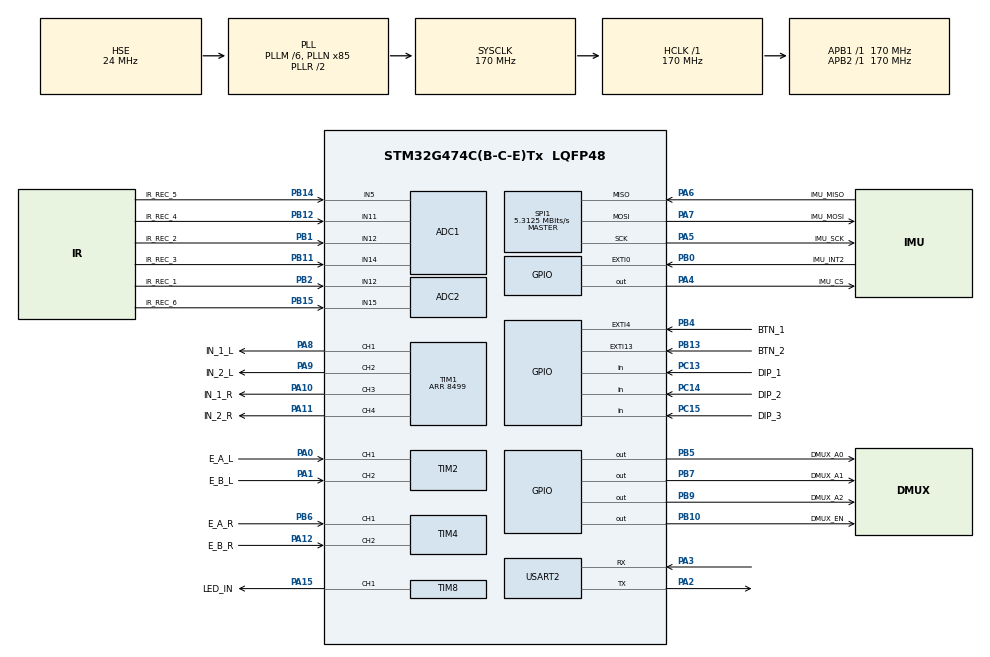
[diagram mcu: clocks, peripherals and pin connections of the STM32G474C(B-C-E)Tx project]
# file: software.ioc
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ADC1.Channel-0\#ChannelRegularConversion=ADC_CHANNEL_12
ADC1.Channel-1\#ChannelRegularConversion=ADC_CHANNEL_14
ADC1.Channel-2\#ChannelRegularConversion=ADC_CHANNEL_11
ADC1.Channel-3\#ChannelRegularConversion=ADC_CHANNEL_5
ADC1.ClockPrescaler=ADC_CLOCK_ASYNC_DIV4
ADC1.ContinuousConvMode=DISABLE
ADC1.DMAContinuousRequests=ENABLE
ADC1.EOCSelection=ADC_EOC_SEQ_CONV
ADC1.NbrOfConversion=4
ADC1.NbrOfConversionFlag=1
ADC1.OffsetNumber-0\#ChannelRegularConversion=ADC_OFFSET_NONE
ADC1.OffsetNumber-1\#ChannelRegularConversion=ADC_OFFSET_NONE
ADC1.OffsetNumber-2\#ChannelRegularConversion=ADC_OFFSET_NONE
ADC1.OffsetNumber-3\#ChannelRegularConversion=ADC_OFFSET_NONE
ADC1.Overrun=ADC_OVR_DATA_OVERWRITTEN
ADC1.Rank-0\#ChannelRegularConversion=1
ADC1.Rank-1\#ChannelRegularConversion=2
ADC1.Rank-2\#ChannelRegularConversion=3
ADC1.Rank-3\#ChannelRegularConversion=4
ADC1.SamplingTime-0\#ChannelRegularConversion=ADC_SAMPLETIME_92CYCLES_5
ADC1.SamplingTime-1\#ChannelRegularConversion=ADC_SAMPLETIME_92CYCLES_5
ADC1.SamplingTime-2\#ChannelRegularConversion=ADC_SAMPLETIME_92CYCLES_5
ADC1.SamplingTime-3\#ChannelRegularConversion=ADC_SAMPLETIME_92CYCLES_5
ADC1.master=1
ADC2.Channel-2\#ChannelRegularConversion=ADC_CHANNEL_12
ADC2.Channel-3\#ChannelRegularConversion=ADC_CHANNEL_15
ADC2.ClockPrescaler=ADC_CLOCK_ASYNC_DIV4
ADC2.ContinuousConvMode=DISABLE
ADC2.DMAContinuousRequests=ENABLE
ADC2.EOCSelection=ADC_EOC_SEQ_CONV
ADC2.NbrOfConversion=2
ADC2.NbrOfConversionFlag=1
ADC2.OffsetNumber-2\#ChannelRegularConversion=ADC_OFFSET_NONE
ADC2.OffsetNumber-3\#ChannelRegularConversion=ADC_OFFSET_NONE
ADC2.Overrun=ADC_OVR_DATA_OVERWRITTEN
ADC2.Rank-2\#ChannelRegularConversion=1
ADC2.Rank-3\#ChannelRegularConversion=2
ADC2.SamplingTime-2\#ChannelRegularConversion=ADC_SAMPLETIME_92CYCLES_5
ADC2.SamplingTime-3\#ChannelRegularConversion=ADC_SAMPLETIME_92CYCLES_5
Dma.ADC1.0.Direction=DMA_PERIPH_TO_MEMORY
Dma.ADC1.0.EventEnable=DISABLE
Dma.ADC1.0.Instance=DMA1_Channel1
Dma.ADC1.0.MemDataAlignment=DMA_MDATAALIGN_HALFWORD
Dma.ADC1.0.MemInc=DMA_MINC_ENABLE
Dma.ADC1.0.Mode=DMA_NORMAL
Dma.ADC1.0.PeriphDataAlignment=DMA_PDATAALIGN_HALFWORD
Dma.ADC1.0.PeriphInc=DMA_PINC_DISABLE
Dma.ADC1.0.Polarity=HAL_DMAMUX_REQ_GEN_RISING
Dma.ADC1.0.Priority=DMA_PRIORITY_HIGH
Dma.ADC1.0.RequestNumber=1
Dma.ADC1.0.SignalID=NONE
Dma.ADC1.0.SyncEnable=DISABLE
Dma.ADC1.0.SyncPolarity=HAL_DMAMUX_SYNC_NO_EVENT
Dma.ADC1.0.SyncRequestNumber=1
Dma.ADC1.0.SyncSignalID=NONE
Dma.ADC2.4.Direction=DMA_PERIPH_TO_MEMORY
Dma.ADC2.4.EventEnable=DISABLE
Dma.ADC2.4.Instance=DMA1_Channel2
Dma.ADC2.4.MemDataAlignment=DMA_MDATAALIGN_HALFWORD
Dma.ADC2.4.MemInc=DMA_MINC_ENABLE
Dma.ADC2.4.Mode=DMA_NORMAL
Dma.ADC2.4.PeriphDataAlignment=DMA_PDATAALIGN_HALFWORD
Dma.ADC2.4.PeriphInc=DMA_PINC_DISABLE
Dma.ADC2.4.Polarity=HAL_DMAMUX_REQ_GEN_RISING
Dma.ADC2.4.Priority=DMA_PRIORITY_HIGH
Dma.ADC2.4.RequestNumber=1
Dma.ADC2.4.SignalID=NONE
Dma.ADC2.4.SyncEnable=DISABLE
Dma.ADC2.4.SyncPolarity=HAL_DMAMUX_SYNC_NO_EVENT
Dma.ADC2.4.SyncRequestNumber=1
Dma.ADC2.4.SyncSignalID=NONE
Dma.Request0=ADC1
Dma.Request1=TIM8_CH1
Dma.Request2=USART2_RX
Dma.Request3=USART2_TX
Dma.Request4=ADC2
Dma.TIM8_CH1.1.Direction=DMA_MEMORY_TO_PERIPH
Dma.TIM8_CH1.1.EventEnable=DISABLE
Dma.TIM8_CH1.1.Instance=DMA1_Channel3
Dma.TIM8_CH1.1.MemDataAlignment=DMA_MDATAALIGN_HALFWORD
Dma.TIM8_CH1.1.MemInc=DMA_MINC_ENABLE
Dma.TIM8_CH1.1.Mode=DMA_NORMAL
Dma.TIM8_CH1.1.PeriphDataAlignment=DMA_PDATAALIGN_HALFWORD
Dma.TIM8_CH1.1.PeriphInc=DMA_PINC_DISABLE
Dma.TIM8_CH1.1.Polarity=HAL_DMAMUX_REQ_GEN_RISING
Dma.TIM8_CH1.1.Priority=DMA_PRIORITY_HIGH
Dma.TIM8_CH1.1.RequestNumber=1
Dma.TIM8_CH1.1.SignalID=NONE
Dma.TIM8_CH1.1.SyncEnable=DISABLE
Dma.TIM8_CH1.1.SyncPolarity=HAL_DMAMUX_SYNC_NO_EVENT
Dma.TIM8_CH1.1.SyncRequestNumber=1
Dma.TIM8_CH1.1.SyncSignalID=NONE
Dma.USART2_RX.2.Direction=DMA_PERIPH_TO_MEMORY
Dma.USART2_RX.2.EventEnable=DISABLE
Dma.USART2_RX.2.Instance=DMA1_Channel4
Dma.USART2_RX.2.MemDataAlignment=DMA_MDATAALIGN_BYTE
Dma.USART2_RX.2.MemInc=DMA_MINC_ENABLE
Dma.USART2_RX.2.Mode=DMA_CIRCULAR
Dma.USART2_RX.2.PeriphDataAlignment=DMA_PDATAALIGN_BYTE
Dma.USART2_RX.2.PeriphInc=DMA_PINC_DISABLE
Dma.USART2_RX.2.Polarity=HAL_DMAMUX_REQ_GEN_RISING
Dma.USART2_RX.2.Priority=DMA_PRIORITY_MEDIUM
Dma.USART2_RX.2.RequestNumber=1
Dma.USART2_RX.2.SignalID=NONE
Dma.USART2_RX.2.SyncEnable=DISABLE
Dma.USART2_RX.2.SyncPolarity=HAL_DMAMUX_SYNC_NO_EVENT
Dma.USART2_RX.2.SyncRequestNumber=1
Dma.USART2_RX.2.SyncSignalID=NONE
Dma.USART2_TX.3.Direction=DMA_MEMORY_TO_PERIPH
Dma.USART2_TX.3.EventEnable=DISABLE
Dma.USART2_TX.3.Instance=DMA1_Channel5
Dma.USART2_TX.3.MemDataAlignment=DMA_MDATAALIGN_BYTE
Dma.USART2_TX.3.MemInc=DMA_MINC_ENABLE
Dma.USART2_TX.3.Mode=DMA_NORMAL
Dma.USART2_TX.3.PeriphDataAlignment=DMA_PDATAALIGN_BYTE
Dma.USART2_TX.3.PeriphInc=DMA_PINC_DISABLE
Dma.USART2_TX.3.Polarity=HAL_DMAMUX_REQ_GEN_RISING
Dma.USART2_TX.3.Priority=DMA_PRIORITY_MEDIUM
Dma.USART2_TX.3.RequestNumber=1
Dma.USART2_TX.3.SignalID=NONE
Dma.USART2_TX.3.SyncEnable=DISABLE
Dma.USART2_TX.3.SyncPolarity=HAL_DMAMUX_SYNC_NO_EVENT
Dma.USART2_TX.3.SyncRequestNumber=1
Dma.USART2_TX.3.SyncSignalID=NONE
Mcu.Family=STM32G4
Mcu.Name=STM32G474C(B-C-E)Tx
Mcu.Package=LQFP48
NVIC.DMA1_Channel1_IRQn=true\:0\:0\:false\:false\:true\:false\:true\:true
NVIC.DMA1_Channel2_IRQn=true\:0\:0\:false\:false\:true\:false\:true\:true
NVIC.DMA1_Channel3_IRQn=true\:0\:0\:false\:false\:true\:false\:true\:true
NVIC.DMA1_Channel4_IRQn=true\:0\:0\:false\:false\:true\:false\:true\:true
NVIC.DMA1_Channel5_IRQn=true\:0\:0\:false\:false\:true\:false\:true\:true
NVIC.EXTI0_IRQn=true\:5\:0\:true\:false\:true\:true\:true\:true
NVIC.EXTI15_10_IRQn=true\:5\:0\:true\:false\:true\:true\:true\:true
NVIC.EXTI4_IRQn=true\:5\:0\:true\:false\:true\:true\:true\:true
NVIC.PriorityGroup=NVIC_PRIORITYGROUP_4
NVIC.TIM1_UP_TIM16_IRQn=true\:0\:0\:false\:false\:true\:true\:true\:true
NVIC.TIM3_IRQn=true\:5\:0\:true\:false\:true\:true\:true\:true
NVIC.TIM6_DAC_IRQn=true\:0\:0\:false\:false\:true\:true\:true\:true
NVIC.TIM7_DAC_IRQn=true\:5\:0\:true\:false\:true\:true\:true\:true
NVIC.USART2_IRQn=true\:0\:0\:false\:false\:true\:false\:true\:true
PA0.GPIO_Label=E_A_L
PA0.Signal=S_TIM2_CH1
PA1.GPIO_Label=E_B_L
PA1.Signal=S_TIM2_CH2
PA10.GPIO_Label=IN_1_R
PA10.Signal=S_TIM1_CH3
PA11.GPIO_Label=IN_2_R
PA11.Signal=S_TIM1_CH4
PA12.GPIO_Label=E_B_R
PA12.Signal=S_TIM4_CH2
PA13.Mode=Trace_Asynchronous_SW
PA13.Signal=SYS_JTMS-SWDIO
PA14.Mode=Trace_Asynchronous_SW
PA14.Signal=SYS_JTCK-SWCLK
PA15.GPIO_Label=LED_IN
PA15.GPIO_Speed=GPIO_SPEED_FREQ_VERY_HIGH
PA15.Signal=S_TIM8_CH1
PA2.Mode=Asynchronous
PA2.Signal=USART2_TX
PA3.Mode=Asynchronous
PA3.Signal=USART2_RX
PA4.GPIO_Label=IMU_CS
PA4.GPIO_PuPd=GPIO_PULLUP
PA4.PinState=GPIO_PIN_SET
PA4.Signal=GPIO_Output
PA5.GPIO_Label=IMU_SCK
PA5.Mode=Full_Duplex_Master
PA5.Signal=SPI1_SCK
PA6.GPIO_Label=IMU_MISO
PA6.Mode=Full_Duplex_Master
PA6.Signal=SPI1_MISO
PA7.GPIO_Label=IMU_MOSI
PA7.Mode=Full_Duplex_Master
PA7.Signal=SPI1_MOSI
PA8.GPIO_Label=IN_1_L
PA8.Signal=S_TIM1_CH1
PA9.GPIO_Label=IN_2_L
PA9.Signal=S_TIM1_CH2
PB0.GPIO_Label=IMU_INT2
PB0.Signal=GPXTI0
PB1.GPIO_Label=IR_REC_2
PB1.Mode=IN12-Single-Ended
PB1.Signal=ADC1_IN12
PB10.GPIO_Label=DMUX_EN
PB10.Signal=GPIO_Output
PB11.GPIO_Label=IR_REC_3
PB11.Mode=IN14-Single-Ended
PB11.Signal=ADC1_IN14
PB12.GPIO_Label=IR_REC_4
PB12.Mode=IN11-Single-Ended
PB12.Signal=ADC1_IN11
PB13.GPIO_Label=BTN_2
PB13.GPIO_ModeDefaultEXTI=GPIO_MODE_IT_FALLING
PB13.Signal=GPXTI13
PB14.GPIO_Label=IR_REC_5
PB14.Mode=IN5-Single-Ended
PB14.Signal=ADC1_IN5
PB15.GPIO_Label=IR_REC_6
PB15.Mode=IN15-Single-Ended
PB15.Signal=ADC2_IN15
PB2.GPIO_Label=IR_REC_1
PB2.Mode=IN12-Single-Ended
PB2.Signal=ADC2_IN12
PB3.Mode=Trace_Asynchronous_SW
PB3.Signal=SYS_JTDO-SWO
PB4.GPIO_Label=BTN_1
PB4.GPIO_ModeDefaultEXTI=GPIO_MODE_IT_FALLING
PB4.Signal=GPXTI4
PB5.GPIO_Label=DMUX_A0
PB5.Signal=GPIO_Output
PB6.GPIO_Label=E_A_R
PB6.Signal=S_TIM4_CH1
PB7.GPIO_Label=DMUX_A1
PB7.Signal=GPIO_Output
PB9.GPIO_Label=DMUX_A2
PB9.Signal=GPIO_Output
PC13.GPIO_Label=DIP_1
PC13.Signal=GPIO_Input
PC14-OSC32_IN.GPIO_Label=DIP_2
PC14-OSC32_IN.Signal=GPIO_Input
PC15-OSC32_OUT.GPIO_Label=DIP_3
PC15-OSC32_OUT.Signal=GPIO_Input
PF0-OSC_IN.Mode=HSE-External-Oscillator
PF0-OSC_IN.Signal=RCC_OSC_IN
PF1-OSC_OUT.Mode=HSE-External-Oscillator
PF1-OSC_OUT.Signal=RCC_OSC_OUT
ProjectManager.HeapSize=0x200
ProjectManager.StackSize=0x400
ProjectManager.TargetToolchain=STM32CubeIDE
RCC.ADC12Freq_Value=170000000
RCC.ADC345Freq_Value=170000000
RCC.AHBFreq_Value=170000000
RCC.APB1Freq_Value=170000000
RCC.APB1TimFreq_Value=170000000
RCC.APB2Freq_Value=170000000
RCC.APB2TimFreq_Value=170000000
RCC.CortexFreq_Value=170000000
RCC.EXTERNAL_CLOCK_VALUE=12288000
RCC.HCLKFreq_Value=170000000
RCC.HSE_VALUE=24000000
RCC.HSI48_VALUE=48000000
RCC.HSI_VALUE=16000000
RCC.LSE_VALUE=32768
RCC.PLLM=RCC_PLLM_DIV6
RCC.PLLN=85
RCC.PLLSourceVirtual=RCC_PLLSOURCE_HSE
RCC.SYSCLKFreq_VALUE=170000000
RCC.SYSCLKSource=RCC_SYSCLKSOURCE_PLLCLK
RCC.USBFreq_Value=170000000
RCC.VCOOutputFreq_Value=340000000
SH.S_TIM1_CH1.0=TIM1_CH1,PWM Generation1 CH1
SH.S_TIM1_CH2.0=TIM1_CH2,PWM Generation2 CH2
SH.S_TIM1_CH3.0=TIM1_CH3,PWM Generation3 CH3
SH.S_TIM1_CH4.0=TIM1_CH4,PWM Generation4 CH4
SH.S_TIM2_CH1.0=TIM2_CH1,Encoder_Interface
SH.S_TIM2_CH2.0=TIM2_CH2,Encoder_Interface
SH.S_TIM4_CH1.0=TIM4_CH1,Encoder_Interface
SH.S_TIM4_CH2.0=TIM4_CH2,Encoder_Interface
SH.S_TIM8_CH1.0=TIM8_CH1,PWM Generation1 CH1
SPI1.BaudRatePrescaler=SPI_BAUDRATEPRESCALER_32
SPI1.CLKPhase=SPI_PHASE_2EDGE
SPI1.CLKPolarity=SPI_POLARITY_HIGH
SPI1.CalculateBaudRate=5.3125 MBits/s
SPI1.DataSize=SPI_DATASIZE_8BIT
SPI1.Direction=SPI_DIRECTION_2LINES
SPI1.Mode=SPI_MODE_MASTER
SPI1.VirtualType=VM_MASTER
TIM1.Channel-PWM\ Generation1\ CH1=TIM_CHANNEL_1
TIM1.Channel-PWM\ Generation2\ CH2=TIM_CHANNEL_2
TIM1.Channel-PWM\ Generation3\ CH3=TIM_CHANNEL_3
TIM1.Channel-PWM\ Generation4\ CH4=TIM_CHANNEL_4
TIM1.PeriodNoDither=8499
TIM16.Prescaler=169
TIM2.EncoderMode=TIM_ENCODERMODE_TI12
TIM3.PeriodNoDither=9
TIM3.Prescaler=16999
TIM4.EncoderMode=TIM_ENCODERMODE_TI12
TIM6.AutoReloadPreload=TIM_AUTORELOAD_PRELOAD_ENABLE
TIM6.PeriodNoDither=99
TIM6.Prescaler=16999
TIM7.AutoReloadPreload=TIM_AUTORELOAD_PRELOAD_ENABLE
TIM7.PeriodNoDither=199
TIM7.Prescaler=16999
TIM8.AutoReloadPreload=TIM_AUTORELOAD_PRELOAD_ENABLE
TIM8.Channel-PWM\ Generation1\ CH1=TIM_CHANNEL_1
TIM8.PeriodNoDither=211
USART2.VirtualMode-Asynchronous=VM_ASYNC
VP_SYS_VS_DBSignals.Mode=DisableDeadBatterySignals
VP_TIM16_VS_ClockSourceINT.Mode=Enable_Timer
VP_TIM1_VS_ClockSourceINT.Mode=Internal
VP_TIM3_VS_ClockSourceINT.Mode=Internal
VP_TIM6_VS_ClockSourceINT.Mode=Enable_Timer
VP_TIM7_VS_ClockSourceINT.Mode=Enable_Timer
VP_TIM8_VS_ClockSourceINT.Mode=Internal
board=custom

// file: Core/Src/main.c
/* USER CODE BEGIN Header */
/**
  ******************************************************************************
  * @file           : main.c
  * @brief          : Main program body
  ******************************************************************************
  * @attention
  *
  * Copyright (c) 2026 STMicroelectronics.
  * All rights reserved.
  *
  * This software is licensed under terms that can be found in the LICENSE file
  * in the root directory of this software component.
  * If no LICENSE file comes with this software, it is provided AS-IS.
  *
  ******************************************************************************
  */
/* USER CODE END Header */
#include "main.h"

/* USER CODE BEGIN Includes */

#include "app.h"

/* USER CODE END Includes */

ADC_HandleTypeDef hadc1;
ADC_HandleTypeDef hadc2;
DMA_HandleTypeDef hdma_adc1;
DMA_HandleTypeDef hdma_adc2;

SPI_HandleTypeDef hspi1;

TIM_HandleTypeDef htim1;
TIM_HandleTypeDef htim2;
TIM_HandleTypeDef htim3;
TIM_HandleTypeDef htim4;
TIM_HandleTypeDef htim6;
TIM_HandleTypeDef htim7;
TIM_HandleTypeDef htim8;
TIM_HandleTypeDef htim16;
DMA_HandleTypeDef hdma_tim8_ch1;

UART_HandleTypeDef huart2;
DMA_HandleTypeDef hdma_usart2_rx;
DMA_HandleTypeDef hdma_usart2_tx;

void SystemClock_Config(void);
static void MX_GPIO_Init(void);
static void MX_DMA_Init(void);
static void MX_ADC1_Init(void);
static void MX_ADC2_Init(void);
static void MX_SPI1_Init(void);
static void MX_TIM1_Init(void);
static void MX_TIM2_Init(void);
static void MX_TIM4_Init(void);
static void MX_TIM8_Init(void);
static void MX_USART2_UART_Init(void);
static void MX_TIM7_Init(void);
static void MX_TIM6_Init(void);
static void MX_TIM3_Init(void);
static void MX_TIM16_Init(void);

int main(void)
{

  /* MCU Configuration--------------------------------------------------------*/

  /* Reset of all peripherals, Initializes the Flash interface and the Systick. */
  HAL_Init();

  /* Configure the system clock */
  SystemClock_Config();

  /* Initialize all configured peripherals */
  MX_GPIO_Init();
  MX_DMA_Init();
  MX_ADC1_Init();
  MX_ADC2_Init();
  MX_SPI1_Init();
  MX_TIM1_Init();
  MX_TIM2_Init();
  MX_TIM3_Init();
  MX_TIM4_Init();
  MX_TIM6_Init();
  MX_TIM7_Init();
  MX_TIM8_Init();
  MX_TIM16_Init();
  MX_USART2_UART_Init();
  /* USER CODE BEGIN 2 */

  App_Init();

  /* USER CODE END 2 */

  /* Infinite loop */
  /* USER CODE BEGIN WHILE */

  while (1)
  {
	  App_Loop();
  }

    /* USER CODE END WHILE */

    /* USER CODE BEGIN 3 */
//  }
  /* USER CODE END 3 */
}

void SystemClock_Config(void)
{
  RCC_OscInitTypeDef RCC_OscInitStruct = {0};
  RCC_ClkInitTypeDef RCC_ClkInitStruct = {0};

  /** Configure the main internal regulator output voltage
  */
  HAL_PWREx_ControlVoltageScaling(PWR_REGULATOR_VOLTAGE_SCALE1_BOOST);

  /** Initializes the RCC Oscillators according to the specified parameters
  * in the RCC_OscInitTypeDef structure.
  */
  RCC_OscInitStruct.OscillatorType = RCC_OSCILLATORTYPE_HSE;
  RCC_OscInitStruct.HSEState = RCC_HSE_ON;
  RCC_OscInitStruct.PLL.PLLState = RCC_PLL_ON;
  RCC_OscInitStruct.PLL.PLLSource = RCC_PLLSOURCE_HSE;
  RCC_OscInitStruct.PLL.PLLM = RCC_PLLM_DIV6;
  RCC_OscInitStruct.PLL.PLLN = 85;
  RCC_OscInitStruct.PLL.PLLP = RCC_PLLP_DIV2;
  RCC_OscInitStruct.PLL.PLLQ = RCC_PLLQ_DIV2;
  RCC_OscInitStruct.PLL.PLLR = RCC_PLLR_DIV2;
  if (HAL_RCC_OscConfig(&RCC_OscInitStruct) != HAL_OK)
  {
    Error_Handler();
  }

  /** Initializes the CPU, AHB and APB buses clocks
  */
  RCC_ClkInitStruct.ClockType = RCC_CLOCKTYPE_HCLK|RCC_CLOCKTYPE_SYSCLK
                              |RCC_CLOCKTYPE_PCLK1|RCC_CLOCKTYPE_PCLK2;
  RCC_ClkInitStruct.SYSCLKSource = RCC_SYSCLKSOURCE_PLLCLK;
  RCC_ClkInitStruct.AHBCLKDivider = RCC_SYSCLK_DIV1;
  RCC_ClkInitStruct.APB1CLKDivider = RCC_HCLK_DIV1;
  RCC_ClkInitStruct.APB2CLKDivider = RCC_HCLK_DIV1;

  if (HAL_RCC_ClockConfig(&RCC_ClkInitStruct, FLASH_LATENCY_4) != HAL_OK)
  {
    Error_Handler();
  }
}

static void MX_ADC1_Init(void)
{

  ADC_MultiModeTypeDef multimode = {0};
  ADC_ChannelConfTypeDef sConfig = {0};

  /** Common config
  */
  hadc1.Instance = ADC1;
  hadc1.Init.ClockPrescaler = ADC_CLOCK_ASYNC_DIV4;
  hadc1.Init.Resolution = ADC_RESOLUTION_12B;
  hadc1.Init.DataAlign = ADC_DATAALIGN_RIGHT;
  hadc1.Init.GainCompensation = 0;
  hadc1.Init.ScanConvMode = ADC_SCAN_ENABLE;
  hadc1.Init.EOCSelection = ADC_EOC_SEQ_CONV;
  hadc1.Init.LowPowerAutoWait = DISABLE;
  hadc1.Init.ContinuousConvMode = DISABLE;
  hadc1.Init.NbrOfConversion = 4;
  hadc1.Init.DiscontinuousConvMode = DISABLE;
  hadc1.Init.ExternalTrigConv = ADC_SOFTWARE_START;
  hadc1.Init.ExternalTrigConvEdge = ADC_EXTERNALTRIGCONVEDGE_NONE;
  hadc1.Init.DMAContinuousRequests = ENABLE;
  hadc1.Init.Overrun = ADC_OVR_DATA_OVERWRITTEN;
  hadc1.Init.OversamplingMode = DISABLE;
  if (HAL_ADC_Init(&hadc1) != HAL_OK)
  {
    Error_Handler();
  }

  /** Configure the ADC multi-mode
  */
  multimode.Mode = ADC_MODE_INDEPENDENT;
  if (HAL_ADCEx_MultiModeConfigChannel(&hadc1, &multimode) != HAL_OK)
  {
    Error_Handler();
  }

  /** Configure Regular Channel
  */
  sConfig.Channel = ADC_CHANNEL_12;
  sConfig.Rank = ADC_REGULAR_RANK_1;
  sConfig.SamplingTime = ADC_SAMPLETIME_92CYCLES_5;
  sConfig.SingleDiff = ADC_SINGLE_ENDED;
  sConfig.OffsetNumber = ADC_OFFSET_NONE;
  sConfig.Offset = 0;
  if (HAL_ADC_ConfigChannel(&hadc1, &sConfig) != HAL_OK)
  {
    Error_Handler();
  }

  /** Configure Regular Channel
  */
  sConfig.Channel = ADC_CHANNEL_14;
  sConfig.Rank = ADC_REGULAR_RANK_2;
  if (HAL_ADC_ConfigChannel(&hadc1, &sConfig) != HAL_OK)
  {
    Error_Handler();
  }

  /** Configure Regular Channel
  */
  sConfig.Channel = ADC_CHANNEL_11;
  sConfig.Rank = ADC_REGULAR_RANK_3;
  if (HAL_ADC_ConfigChannel(&hadc1, &sConfig) != HAL_OK)
  {
    Error_Handler();
  }

  /** Configure Regular Channel
  */
  sConfig.Channel = ADC_CHANNEL_5;
  sConfig.Rank = ADC_REGULAR_RANK_4;
  if (HAL_ADC_ConfigChannel(&hadc1, &sConfig) != HAL_OK)
  {
    Error_Handler();
  }

}

static void MX_ADC2_Init(void)
{

  ADC_ChannelConfTypeDef sConfig = {0};

  /** Common config
  */
  hadc2.Instance = ADC2;
  hadc2.Init.ClockPrescaler = ADC_CLOCK_ASYNC_DIV4;
  hadc2.Init.Resolution = ADC_RESOLUTION_12B;
  hadc2.Init.DataAlign = ADC_DATAALIGN_RIGHT;
  hadc2.Init.GainCompensation = 0;
  hadc2.Init.ScanConvMode = ADC_SCAN_ENABLE;
  hadc2.Init.EOCSelection = ADC_EOC_SEQ_CONV;
  hadc2.Init.LowPowerAutoWait = DISABLE;
  hadc2.Init.ContinuousConvMode = DISABLE;
  hadc2.Init.NbrOfConversion = 2;
  hadc2.Init.DiscontinuousConvMode = DISABLE;
  hadc2.Init.ExternalTrigConv = ADC_SOFTWARE_START;
  hadc2.Init.ExternalTrigConvEdge = ADC_EXTERNALTRIGCONVEDGE_NONE;
  hadc2.Init.DMAContinuousRequests = ENABLE;
  hadc2.Init.Overrun = ADC_OVR_DATA_OVERWRITTEN;
  hadc2.Init.OversamplingMode = DISABLE;
  if (HAL_ADC_Init(&hadc2) != HAL_OK)
  {
    Error_Handler();
  }

  /** Configure Regular Channel
  */
  sConfig.Channel = ADC_CHANNEL_12;
  sConfig.Rank = ADC_REGULAR_RANK_1;
  sConfig.SamplingTime = ADC_SAMPLETIME_92CYCLES_5;
  sConfig.SingleDiff = ADC_SINGLE_ENDED;
  sConfig.OffsetNumber = ADC_OFFSET_NONE;
  sConfig.Offset = 0;
  if (HAL_ADC_ConfigChannel(&hadc2, &sConfig) != HAL_OK)
  {
    Error_Handler();
  }

  /** Configure Regular Channel
  */
  sConfig.Channel = ADC_CHANNEL_15;
  sConfig.Rank = ADC_REGULAR_RANK_2;
  if (HAL_ADC_ConfigChannel(&hadc2, &sConfig) != HAL_OK)
  {
    Error_Handler();
  }

}

static void MX_SPI1_Init(void)
{

  /* SPI1 parameter configuration*/
  hspi1.Instance = SPI1;
  hspi1.Init.Mode = SPI_MODE_MASTER;
  hspi1.Init.Direction = SPI_DIRECTION_2LINES;
  hspi1.Init.DataSize = SPI_DATASIZE_8BIT;
  hspi1.Init.CLKPolarity = SPI_POLARITY_HIGH;
  hspi1.Init.CLKPhase = SPI_PHASE_2EDGE;
  hspi1.Init.NSS = SPI_NSS_SOFT;
  hspi1.Init.BaudRatePrescaler = SPI_BAUDRATEPRESCALER_32;
  hspi1.Init.FirstBit = SPI_FIRSTBIT_MSB;
  hspi1.Init.TIMode = SPI_TIMODE_DISABLE;
  hspi1.Init.CRCCalculation = SPI_CRCCALCULATION_DISABLE;
  hspi1.Init.CRCPolynomial = 7;
  hspi1.Init.CRCLength = SPI_CRC_LENGTH_DATASIZE;
  hspi1.Init.NSSPMode = SPI_NSS_PULSE_DISABLE;
  if (HAL_SPI_Init(&hspi1) != HAL_OK)
  {
    Error_Handler();
  }

}

static void MX_TIM1_Init(void)
{

  TIM_ClockConfigTypeDef sClockSourceConfig = {0};
  TIM_MasterConfigTypeDef sMasterConfig = {0};
  TIM_OC_InitTypeDef sConfigOC = {0};
  TIM_BreakDeadTimeConfigTypeDef sBreakDeadTimeConfig = {0};

  htim1.Instance = TIM1;
  htim1.Init.Prescaler = 0;
  htim1.Init.CounterMode = TIM_COUNTERMODE_UP;
  htim1.Init.Period = 8499;
  htim1.Init.ClockDivision = TIM_CLOCKDIVISION_DIV1;
  htim1.Init.RepetitionCounter = 0;
  htim1.Init.AutoReloadPreload = TIM_AUTORELOAD_PRELOAD_DISABLE;
  if (HAL_TIM_Base_Init(&htim1) != HAL_OK)
  {
    Error_Handler();
  }
  sClockSourceConfig.ClockSource = TIM_CLOCKSOURCE_INTERNAL;
  if (HAL_TIM_ConfigClockSource(&htim1, &sClockSourceConfig) != HAL_OK)
  {
    Error_Handler();
  }
  if (HAL_TIM_PWM_Init(&htim1) != HAL_OK)
  {
    Error_Handler();
  }
  sMasterConfig.MasterOutputTrigger = TIM_TRGO_RESET;
  sMasterConfig.MasterOutputTrigger2 = TIM_TRGO2_RESET;
  sMasterConfig.MasterSlaveMode = TIM_MASTERSLAVEMODE_DISABLE;
  if (HAL_TIMEx_MasterConfigSynchronization(&htim1, &sMasterConfig) != HAL_OK)
  {
    Error_Handler();
  }
  sConfigOC.OCMode = TIM_OCMODE_PWM1;
  sConfigOC.Pulse = 0;
  sConfigOC.OCPolarity = TIM_OCPOLARITY_HIGH;
  sConfigOC.OCNPolarity = TIM_OCNPOLARITY_HIGH;
  sConfigOC.OCFastMode = TIM_OCFAST_DISABLE;
  sConfigOC.OCIdleState = TIM_OCIDLESTATE_RESET;
  sConfigOC.OCNIdleState = TIM_OCNIDLESTATE_RESET;
  if (HAL_TIM_PWM_ConfigChannel(&htim1, &sConfigOC, TIM_CHANNEL_1) != HAL_OK)
  {
    Error_Handler();
  }
  if (HAL_TIM_PWM_ConfigChannel(&htim1, &sConfigOC, TIM_CHANNEL_2) != HAL_OK)
  {
    Error_Handler();
  }
  if (HAL_TIM_PWM_ConfigChannel(&htim1, &sConfigOC, TIM_CHANNEL_3) != HAL_OK)
  {
    Error_Handler();
  }
  if (HAL_TIM_PWM_ConfigChannel(&htim1, &sConfigOC, TIM_CHANNEL_4) != HAL_OK)
  {
    Error_Handler();
  }
  sBreakDeadTimeConfig.OffStateRunMode = TIM_OSSR_DISABLE;
  sBreakDeadTimeConfig.OffStateIDLEMode = TIM_OSSI_DISABLE;
  sBreakDeadTimeConfig.LockLevel = TIM_LOCKLEVEL_OFF;
  sBreakDeadTimeConfig.DeadTime = 0;
  sBreakDeadTimeConfig.BreakState = TIM_BREAK_DISABLE;
  sBreakDeadTimeConfig.BreakPolarity = TIM_BREAKPOLARITY_HIGH;
  sBreakDeadTimeConfig.BreakFilter = 0;
  sBreakDeadTimeConfig.BreakAFMode = TIM_BREAK_AFMODE_INPUT;
  sBreakDeadTimeConfig.Break2State = TIM_BREAK2_DISABLE;
  sBreakDeadTimeConfig.Break2Polarity = TIM_BREAK2POLARITY_HIGH;
  sBreakDeadTimeConfig.Break2Filter = 0;
  sBreakDeadTimeConfig.Break2AFMode = TIM_BREAK_AFMODE_INPUT;
  sBreakDeadTimeConfig.AutomaticOutput = TIM_AUTOMATICOUTPUT_DISABLE;
  if (HAL_TIMEx_ConfigBreakDeadTime(&htim1, &sBreakDeadTimeConfig) != HAL_OK)
  {
    Error_Handler();
  }
  HAL_TIM_MspPostInit(&htim1);

}

static void MX_TIM2_Init(void)
{

  TIM_Encoder_InitTypeDef sConfig = {0};
  TIM_MasterConfigTypeDef sMasterConfig = {0};

  htim2.Instance = TIM2;
  htim2.Init.Prescaler = 0;
  htim2.Init.CounterMode = TIM_COUNTERMODE_UP;
  htim2.Init.Period = 4294967295;
  htim2.Init.ClockDivision = TIM_CLOCKDIVISION_DIV1;
  htim2.Init.AutoReloadPreload = TIM_AUTORELOAD_PRELOAD_DISABLE;
  sConfig.EncoderMode = TIM_ENCODERMODE_TI12;
  sConfig.IC1Polarity = TIM_ICPOLARITY_RISING;
  sConfig.IC1Selection = TIM_ICSELECTION_DIRECTTI;
  sConfig.IC1Prescaler = TIM_ICPSC_DIV1;
  sConfig.IC1Filter = 0;
  sConfig.IC2Polarity = TIM_ICPOLARITY_RISING;
  sConfig.IC2Selection = TIM_ICSELECTION_DIRECTTI;
  sConfig.IC2Prescaler = TIM_ICPSC_DIV1;
  sConfig.IC2Filter = 0;
  if (HAL_TIM_Encoder_Init(&htim2, &sConfig) != HAL_OK)
  {
    Error_Handler();
  }
  sMasterConfig.MasterOutputTrigger = TIM_TRGO_RESET;
  sMasterConfig.MasterSlaveMode = TIM_MASTERSLAVEMODE_DISABLE;
  if (HAL_TIMEx_MasterConfigSynchronization(&htim2, &sMasterConfig) != HAL_OK)
  {
    Error_Handler();
  }

}

static void MX_TIM3_Init(void)
{

  TIM_ClockConfigTypeDef sClockSourceConfig = {0};
  TIM_MasterConfigTypeDef sMasterConfig = {0};

  htim3.Instance = TIM3;
  htim3.Init.Prescaler = 16999;
  htim3.Init.CounterMode = TIM_COUNTERMODE_UP;
  htim3.Init.Period = 9;
  htim3.Init.ClockDivision = TIM_CLOCKDIVISION_DIV1;
  htim3.Init.AutoReloadPreload = TIM_AUTORELOAD_PRELOAD_DISABLE;
  if (HAL_TIM_Base_Init(&htim3) != HAL_OK)
  {
    Error_Handler();
  }
  sClockSourceConfig.ClockSource = TIM_CLOCKSOURCE_INTERNAL;
  if (HAL_TIM_ConfigClockSource(&htim3, &sClockSourceConfig) != HAL_OK)
  {
    Error_Handler();
  }
  sMasterConfig.MasterOutputTrigger = TIM_TRGO_RESET;
  sMasterConfig.MasterSlaveMode = TIM_MASTERSLAVEMODE_DISABLE;
  if (HAL_TIMEx_MasterConfigSynchronization(&htim3, &sMasterConfig) != HAL_OK)
  {
    Error_Handler();
  }

}

static void MX_TIM4_Init(void)
{

  TIM_Encoder_InitTypeDef sConfig = {0};
  TIM_MasterConfigTypeDef sMasterConfig = {0};

  htim4.Instance = TIM4;
  htim4.Init.Prescaler = 0;
  htim4.Init.CounterMode = TIM_COUNTERMODE_UP;
  htim4.Init.Period = 65535;
  htim4.Init.ClockDivision = TIM_CLOCKDIVISION_DIV1;
  htim4.Init.AutoReloadPreload = TIM_AUTORELOAD_PRELOAD_DISABLE;
  sConfig.EncoderMode = TIM_ENCODERMODE_TI12;
  sConfig.IC1Polarity = TIM_ICPOLARITY_RISING;
  sConfig.IC1Selection = TIM_ICSELECTION_DIRECTTI;
  sConfig.IC1Prescaler = TIM_ICPSC_DIV1;
  sConfig.IC1Filter = 0;
  sConfig.IC2Polarity = TIM_ICPOLARITY_RISING;
  sConfig.IC2Selection = TIM_ICSELECTION_DIRECTTI;
  sConfig.IC2Prescaler = TIM_ICPSC_DIV1;
  sConfig.IC2Filter = 0;
  if (HAL_TIM_Encoder_Init(&htim4, &sConfig) != HAL_OK)
  {
    Error_Handler();
  }
  sMasterConfig.MasterOutputTrigger = TIM_TRGO_RESET;
  sMasterConfig.MasterSlaveMode = TIM_MASTERSLAVEMODE_DISABLE;
  if (HAL_TIMEx_MasterConfigSynchronization(&htim4, &sMasterConfig) != HAL_OK)
  {
    Error_Handler();
  }

}

static void MX_TIM6_Init(void)
{

  TIM_MasterConfigTypeDef sMasterConfig = {0};

  htim6.Instance = TIM6;
  htim6.Init.Prescaler = 16999;
  htim6.Init.CounterMode = TIM_COUNTERMODE_UP;
  htim6.Init.Period = 99;
  htim6.Init.AutoReloadPreload = TIM_AUTORELOAD_PRELOAD_ENABLE;
  if (HAL_TIM_Base_Init(&htim6) != HAL_OK)
  {
    Error_Handler();
  }
  sMasterConfig.MasterOutputTrigger = TIM_TRGO_RESET;
  sMasterConfig.MasterSlaveMode = TIM_MASTERSLAVEMODE_DISABLE;
  if (HAL_TIMEx_MasterConfigSynchronization(&htim6, &sMasterConfig) != HAL_OK)
  {
    Error_Handler();
  }

}

static void MX_TIM7_Init(void)
{

  /* USER CODE BEGIN TIM7_Init 0 */
  __HAL_RCC_TIM7_CLK_ENABLE();
  /* USER CODE END TIM7_Init 0 */

  TIM_MasterConfigTypeDef sMasterConfig = {0};

  htim7.Instance = TIM7;
  htim7.Init.Prescaler = 16999;
  htim7.Init.CounterMode = TIM_COUNTERMODE_UP;
  htim7.Init.Period = 199;
  htim7.Init.AutoReloadPreload = TIM_AUTORELOAD_PRELOAD_ENABLE;
  if (HAL_TIM_Base_Init(&htim7) != HAL_OK)
  {
    Error_Handler();
  }
  sMasterConfig.MasterOutputTrigger = TIM_TRGO_RESET;
  sMasterConfig.MasterSlaveMode = TIM_MASTERSLAVEMODE_DISABLE;
  if (HAL_TIMEx_MasterConfigSynchronization(&htim7, &sMasterConfig) != HAL_OK)
  {
    Error_Handler();
  }

}

static void MX_TIM8_Init(void)
{

  TIM_ClockConfigTypeDef sClockSourceConfig = {0};
  TIM_MasterConfigTypeDef sMasterConfig = {0};
  TIM_OC_InitTypeDef sConfigOC = {0};
  TIM_BreakDeadTimeConfigTypeDef sBreakDeadTimeConfig = {0};

  htim8.Instance = TIM8;
  htim8.Init.Prescaler = 0;
  htim8.Init.CounterMode = TIM_COUNTERMODE_UP;
  htim8.Init.Period = 211;
  htim8.Init.ClockDivision = TIM_CLOCKDIVISION_DIV1;
  htim8.Init.RepetitionCounter = 0;
  htim8.Init.AutoReloadPreload = TIM_AUTORELOAD_PRELOAD_ENABLE;
  if (HAL_TIM_Base_Init(&htim8) != HAL_OK)
  {
    Error_Handler();
  }
  sClockSourceConfig.ClockSource = TIM_CLOCKSOURCE_INTERNAL;
  if (HAL_TIM_ConfigClockSource(&htim8, &sClockSourceConfig) != HAL_OK)
  {
    Error_Handler();
  }
  if (HAL_TIM_PWM_Init(&htim8) != HAL_OK)
  {
    Error_Handler();
  }
  sMasterConfig.MasterOutputTrigger = TIM_TRGO_RESET;
  sMasterConfig.MasterOutputTrigger2 = TIM_TRGO2_RESET;
  sMasterConfig.MasterSlaveMode = TIM_MASTERSLAVEMODE_DISABLE;
  if (HAL_TIMEx_MasterConfigSynchronization(&htim8, &sMasterConfig) != HAL_OK)
  {
    Error_Handler();
  }
  sConfigOC.OCMode = TIM_OCMODE_PWM1;
  sConfigOC.Pulse = 0;
  sConfigOC.OCPolarity = TIM_OCPOLARITY_HIGH;
  sConfigOC.OCNPolarity = TIM_OCNPOLARITY_HIGH;
  sConfigOC.OCFastMode = TIM_OCFAST_DISABLE;
  sConfigOC.OCIdleState = TIM_OCIDLESTATE_RESET;
  sConfigOC.OCNIdleState = TIM_OCNIDLESTATE_RESET;
  if (HAL_TIM_PWM_ConfigChannel(&htim8, &sConfigOC, TIM_CHANNEL_1) != HAL_OK)
  {
    Error_Handler();
  }
  sBreakDeadTimeConfig.OffStateRunMode = TIM_OSSR_DISABLE;
  sBreakDeadTimeConfig.OffStateIDLEMode = TIM_OSSI_DISABLE;
  sBreakDeadTimeConfig.LockLevel = TIM_LOCKLEVEL_OFF;
  sBreakDeadTimeConfig.DeadTime = 0;
  sBreakDeadTimeConfig.BreakState = TIM_BREAK_DISABLE;
  sBreakDeadTimeConfig.BreakPolarity = TIM_BREAKPOLARITY_HIGH;
  sBreakDeadTimeConfig.BreakFilter = 0;
  sBreakDeadTimeConfig.BreakAFMode = TIM_BREAK_AFMODE_INPUT;
  sBreakDeadTimeConfig.Break2State = TIM_BREAK2_DISABLE;
  sBreakDeadTimeConfig.Break2Polarity = TIM_BREAK2POLARITY_HIGH;
  sBreakDeadTimeConfig.Break2Filter = 0;
  sBreakDeadTimeConfig.Break2AFMode = TIM_BREAK_AFMODE_INPUT;
  sBreakDeadTimeConfig.AutomaticOutput = TIM_AUTOMATICOUTPUT_DISABLE;
  if (HAL_TIMEx_ConfigBreakDeadTime(&htim8, &sBreakDeadTimeConfig) != HAL_OK)
  {
    Error_Handler();
  }
  HAL_TIM_MspPostInit(&htim8);

}

static void MX_TIM16_Init(void)
{

  htim16.Instance = TIM16;
  htim16.Init.Prescaler = 169;
  htim16.Init.CounterMode = TIM_COUNTERMODE_UP;
  htim16.Init.Period = 65535;
  htim16.Init.ClockDivision = TIM_CLOCKDIVISION_DIV1;
  htim16.Init.RepetitionCounter = 0;
  htim16.Init.AutoReloadPreload = TIM_AUTORELOAD_PRELOAD_DISABLE;
  if (HAL_TIM_Base_Init(&htim16) != HAL_OK)
  {
    Error_Handler();
  }

}

static void MX_USART2_UART_Init(void)
{

  huart2.Instance = USART2;
  huart2.Init.BaudRate = 115200;
  huart2.Init.WordLength = UART_WORDLENGTH_8B;
  huart2.Init.StopBits = UART_STOPBITS_1;
  huart2.Init.Parity = UART_PARITY_NONE;
  huart2.Init.Mode = UART_MODE_TX_RX;
  huart2.Init.HwFlowCtl = UART_HWCONTROL_NONE;
  huart2.Init.OverSampling = UART_OVERSAMPLING_16;
  huart2.Init.OneBitSampling = UART_ONE_BIT_SAMPLE_DISABLE;
  huart2.Init.ClockPrescaler = UART_PRESCALER_DIV1;
  huart2.AdvancedInit.AdvFeatureInit = UART_ADVFEATURE_NO_INIT;
  if (HAL_UART_Init(&huart2) != HAL_OK)
  {
    Error_Handler();
  }
  if (HAL_UARTEx_SetTxFifoThreshold(&huart2, UART_TXFIFO_THRESHOLD_1_8) != HAL_OK)
  {
    Error_Handler();
  }
  if (HAL_UARTEx_SetRxFifoThreshold(&huart2, UART_RXFIFO_THRESHOLD_1_8) != HAL_OK)
  {
    Error_Handler();
  }
  if (HAL_UARTEx_DisableFifoMode(&huart2) != HAL_OK)
  {
    Error_Handler();
  }

}

static void MX_DMA_Init(void)
{

  /* DMA controller clock enable */
  __HAL_RCC_DMAMUX1_CLK_ENABLE();
  __HAL_RCC_DMA1_CLK_ENABLE();

  /* DMA interrupt init */
  /* DMA1_Channel1_IRQn interrupt configuration */
  HAL_NVIC_SetPriority(DMA1_Channel1_IRQn, 0, 0);
  HAL_NVIC_EnableIRQ(DMA1_Channel1_IRQn);
  /* DMA1_Channel2_IRQn interrupt configuration */
  HAL_NVIC_SetPriority(DMA1_Channel2_IRQn, 0, 0);
  HAL_NVIC_EnableIRQ(DMA1_Channel2_IRQn);
  /* DMA1_Channel3_IRQn interrupt configuration */
  HAL_NVIC_SetPriority(DMA1_Channel3_IRQn, 0, 0);
  HAL_NVIC_EnableIRQ(DMA1_Channel3_IRQn);
  /* DMA1_Channel4_IRQn interrupt configuration */
  HAL_NVIC_SetPriority(DMA1_Channel4_IRQn, 0, 0);
  HAL_NVIC_EnableIRQ(DMA1_Channel4_IRQn);
  /* DMA1_Channel5_IRQn interrupt configuration */
  HAL_NVIC_SetPriority(DMA1_Channel5_IRQn, 0, 0);
  HAL_NVIC_EnableIRQ(DMA1_Channel5_IRQn);

}

static void MX_GPIO_Init(void)
{
  GPIO_InitTypeDef GPIO_InitStruct = {0};

  /* GPIO Ports Clock Enable */
  __HAL_RCC_GPIOC_CLK_ENABLE();
  __HAL_RCC_GPIOF_CLK_ENABLE();
  __HAL_RCC_GPIOA_CLK_ENABLE();
  __HAL_RCC_GPIOB_CLK_ENABLE();

  /*Configure GPIO pin Output Level */
  HAL_GPIO_WritePin(IMU_CS_GPIO_Port, IMU_CS_Pin, GPIO_PIN_SET);

  /*Configure GPIO pin Output Level */
  HAL_GPIO_WritePin(GPIOB, DMUX_EN_Pin|DMUX_A0_Pin|DMUX_A1_Pin|DMUX_A2_Pin, GPIO_PIN_RESET);

  /*Configure GPIO pins : DIP_1_Pin DIP_2_Pin DIP_3_Pin */
  GPIO_InitStruct.Pin = DIP_1_Pin|DIP_2_Pin|DIP_3_Pin;
  GPIO_InitStruct.Mode = GPIO_MODE_INPUT;
  GPIO_InitStruct.Pull = GPIO_NOPULL;
  HAL_GPIO_Init(GPIOC, &GPIO_InitStruct);

  /*Configure GPIO pin : IMU_CS_Pin */
  GPIO_InitStruct.Pin = IMU_CS_Pin;
  GPIO_InitStruct.Mode = GPIO_MODE_OUTPUT_PP;
  GPIO_InitStruct.Pull = GPIO_PULLUP;
  GPIO_InitStruct.Speed = GPIO_SPEED_FREQ_LOW;
  HAL_GPIO_Init(IMU_CS_GPIO_Port, &GPIO_InitStruct);

  /*Configure GPIO pin : IMU_INT2_Pin */
  GPIO_InitStruct.Pin = IMU_INT2_Pin;
  GPIO_InitStruct.Mode = GPIO_MODE_IT_RISING;
  GPIO_InitStruct.Pull = GPIO_NOPULL;
  HAL_GPIO_Init(IMU_INT2_GPIO_Port, &GPIO_InitStruct);

  /*Configure GPIO pins : DMUX_EN_Pin DMUX_A0_Pin DMUX_A1_Pin DMUX_A2_Pin */
  GPIO_InitStruct.Pin = DMUX_EN_Pin|DMUX_A0_Pin|DMUX_A1_Pin|DMUX_A2_Pin;
  GPIO_InitStruct.Mode = GPIO_MODE_OUTPUT_PP;
  GPIO_InitStruct.Pull = GPIO_NOPULL;
  GPIO_InitStruct.Speed = GPIO_SPEED_FREQ_LOW;
  HAL_GPIO_Init(GPIOB, &GPIO_InitStruct);

  /*Configure GPIO pins : BTN_2_Pin BTN_1_Pin */
  GPIO_InitStruct.Pin = BTN_2_Pin|BTN_1_Pin;
  GPIO_InitStruct.Mode = GPIO_MODE_IT_FALLING;
  GPIO_InitStruct.Pull = GPIO_NOPULL;
  HAL_GPIO_Init(GPIOB, &GPIO_InitStruct);

  /* EXTI interrupt init*/
  HAL_NVIC_SetPriority(EXTI0_IRQn, 5, 0);
  HAL_NVIC_EnableIRQ(EXTI0_IRQn);

  HAL_NVIC_SetPriority(EXTI4_IRQn, 5, 0);
  HAL_NVIC_EnableIRQ(EXTI4_IRQn);

  HAL_NVIC_SetPriority(EXTI15_10_IRQn, 5, 0);
  HAL_NVIC_EnableIRQ(EXTI15_10_IRQn);

}

void Error_Handler(void)
{
  __disable_irq();
  while (1)
  {
  }
}
